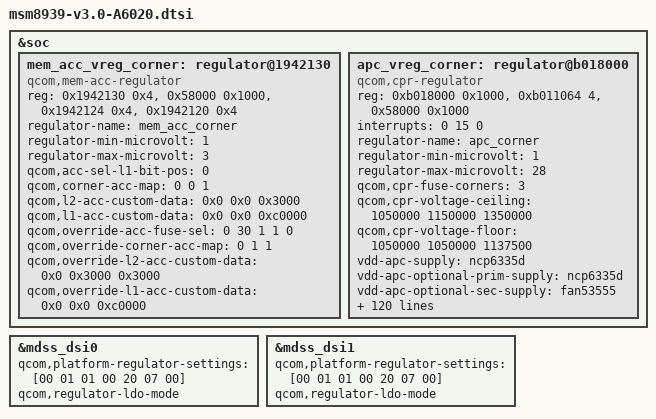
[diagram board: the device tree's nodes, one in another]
/*
 * Copyright (c) 2015, The Linux Foundation. All rights reserved.
 *
 * This program is free software; you can redistribute it and/or modify
 * it under the terms of the GNU General Public License version 2 and
 * only version 2 as published by the Free Software Foundation.
 *
 * This program is distributed in the hope that it will be useful,
 * but WITHOUT ANY WARRANTY; without even the implied warranty of
 * MERCHANTABILITY or FITNESS FOR A PARTICULAR PURPOSE.  See the
 * GNU General Public License for more details.
 */

&soc {
	/delete-node/ regulator@1942130;
        /delete-node/ regulator@b018000;

	mem_acc_vreg_corner: regulator@1942130 {
		compatible = "qcom,mem-acc-regulator";
		reg = <0x1942130 0x4>, <0x58000 0x1000>, <0x1942124 0x4>,  <0x1942120 0x4>;
		reg-names = "acc-sel-l1", "efuse_addr", "acc-l2-custom", "acc-l1-custom";
		regulator-name = "mem_acc_corner";
		regulator-min-microvolt = <1>;
		regulator-max-microvolt = <3>;

		qcom,acc-sel-l1-bit-pos = <0>;
		qcom,corner-acc-map = <0 0 1>;
		qcom,l2-acc-custom-data = <0x0 0x0 0x3000>;
                qcom,l1-acc-custom-data = <0x0 0x0 0xc0000>;

		qcom,override-acc-fuse-sel = <0 30 1 1 0>;
		qcom,override-corner-acc-map = <0 1 1>;
		qcom,override-l2-acc-custom-data = <0x0 0x3000 0x3000>;
                qcom,override-l1-acc-custom-data = <0x0 0x0 0xc0000>;
       };

	apc_vreg_corner: regulator@b018000 {
		compatible = "qcom,cpr-regulator";
		reg = <0xb018000 0x1000>, <0xb011064 4>, <0x58000 0x1000>;
		reg-names = "rbcpr", "rbcpr_clk", "efuse_addr";
		interrupts = <0 15 0>;
		regulator-name = "apc_corner";
		regulator-min-microvolt = <1>;
		regulator-max-microvolt = <28>;

		qcom,cpr-fuse-corners = <3>;
		qcom,cpr-voltage-ceiling = <1050000 1150000 1350000>;
		qcom,cpr-voltage-floor = <1050000 1050000 1137500>;
		vdd-apc-supply = <&ncp6335d>;
		vdd-apc-optional-prim-supply = <&ncp6335d>;
		vdd-apc-optional-sec-supply = <&fan53555>;

		qcom,vdd-mx-corner-map = <4 5 7>;
		qcom,vdd-mx-vmin-method = <4>;
		vdd-mx-supply = <&pm8916_l3_corner_ao>;
		qcom,vdd-mx-vmax = <7>;

		mem-acc-supply = <&mem_acc_vreg_corner>;

		qcom,cpr-ref-clk = <19200>;
		qcom,cpr-timer-delay = <5000>;
		qcom,cpr-timer-cons-up = <0>;
		qcom,cpr-timer-cons-down = <2>;
		qcom,cpr-irq-line = <0>;
		qcom,cpr-step-quotient = <13>;
		qcom,cpr-up-threshold = <0>;
		qcom,cpr-down-threshold = <3>;
		qcom,cpr-idle-clocks = <15>;
		qcom,cpr-gcnt-time = <1>;
		qcom,vdd-apc-step-up-limit = <1>;
		qcom,vdd-apc-step-down-limit = <1>;
		qcom,cpr-apc-volt-step = <6250>;

		qcom,cpr-fuse-row = <27 0>;
		qcom,cpr-fuse-target-quot = <42 24 6>;
		qcom,cpr-fuse-ro-sel = <54 54 54>;
		qcom,cpr-quot-min-diff = <0>;
		qcom,cpr-init-voltage-ref = <1050000 1150000 1350000>;
		qcom,cpr-fuse-init-voltage =
					<27 36 6 0>,
					<27 18 6 0>,
					<27 0 6 0>;
		qcom,cpr-init-voltage-step = <10000>;
		qcom,cpr-scaled-init-voltage-as-ceiling;
		qcom,cpr-corner-map = <1 1 1 2 2 2 2 2 2 2 2 2 2 2 3 3 3 3 3 3
					3 3 3 3 3 3 3 3>;
		qcom,cpr-corner-frequency-map =
					<1 200000000>,
					<2 345600000>,
					<3 400000000>,
					<4 422400000>,
					<5 499200000>,
					<6 533330000>,
					<7 652800000>,
					<8 729600000>,
					<9 800000000>,
					<10 806400000>,
					<11 883200000>,
					<12 960000000>,
					<13 1036800000>,
					<14 1113600000>,
					<15 1190400000>,
					<16 1267200000>,
					<17 1344000000>,
					<18 1363200000>,
					<19 1420800000>,
					<20 1459200000>,
					<21 1497600000>,
					<22 1536000000>,
					<23 1574400000>,
					<24 1612800000>,
					<25 1632000000>,
					<26 1651200000>,
					<27 1689600000>,
					<28 1708800000>;
		qcom,speed-bin-fuse-sel = <1 34 3 0>;
		qcom,cpr-speed-bin-max-corners =
					<0 0 3 14 21>,
					<2 0 3 14 21>,
					<2 2 3 14 20>,
					<4 0 3 14 28>,
					<5 0 3 14 26>,
					<5 6 3 14 26>;
		qcom,cpr-quot-adjust-scaling-factor-max = <900>;
		qcom,fuse-remap-base-row = <1000>;
		qcom,fuse-remap-source =
					<0 29 1 0>, /* speed bit[0]	*/
					<0 50 2 0>, /* speed bit[2:1]	*/
					<0 45 1 0>, /* CPR Rev[0]	*/
					<0 56 1 0>; /* CPR Rev[1]	*/
		qcom,pvs-version-fuse-sel = <1000 0 3 0>;
		qcom,cpr-fuse-revision = <1000 3 2 0>;
		qcom,cpr-fuse-version-map =
		/* <Speed_bits PVS_version CPR_Rev - - -> */
			<0          0          0 0xffffffff 0xffffffff 0xffffffff>,
			<0          0          1 0xffffffff 0xffffffff 0xffffffff>,
			<0          0          2 0xffffffff 0xffffffff 0xffffffff>,
			<0          0          3 0xffffffff 0xffffffff 0xffffffff>,
			<2          0          0 0xffffffff 0xffffffff 0xffffffff>,
			<2          0          1 0xffffffff 0xffffffff 0xffffffff>,
			<2          0          2 0xffffffff 0xffffffff 0xffffffff>,
			<2          0          3 0xffffffff 0xffffffff 0xffffffff>,
			<2          2          0 0xffffffff 0xffffffff 0xffffffff>,
			<2          2          1 0xffffffff 0xffffffff 0xffffffff>,
			<2          2          2 0xffffffff 0xffffffff 0xffffffff>,
			<2          2          3 0xffffffff 0xffffffff 0xffffffff>,
			<0xffffffff 0xffffffff 0 0xffffffff 0xffffffff 0xffffffff>,
			<0xffffffff 0xffffffff 1 0xffffffff 0xffffffff 0xffffffff>,
			<0xffffffff 0xffffffff 2 0xffffffff 0xffffffff 0xffffffff>,
			<0xffffffff 0xffffffff 3 0xffffffff 0xffffffff 0xffffffff>;
		qcom,cpr-init-voltage-adjustment =
					<0   50000  0>,
					<0   20000  0>,
					<0   50000  0>,
					<0   20000  0>,
					<0   20000  0>,
					<0 (-10000) 0>,
					<0   50000  0>,
					<0   20000  0>,
					<0   50000  0>,
					<0   20000  0>,
					<0   50000  0>,
					<0   20000  0>,
					<0   50000  0>,
					<0   20000  0>,
					<0   50000  0>,
					<0   20000  0>;
		qcom,cpr-quotient-adjustment =
					<0  104   (-41)>, /* NOM + 50mv, TURBO - 20mv	*/
					<0   41   (-41)>, /* NOM + 20mv, TURBO - 20mv	*/
					<0  104   (-41)>, /* NOM + 50mv, TURBO - 20mv	*/
					<0   41   (-41)>, /* NOM + 20mv, TURBO - 20mv	*/
					<0  104   (-41)>, /* NOM + 50mv, TURBO - 20mv	*/
					<0   41   (-41)>, /* NOM + 20mv, TURBO - 20mv	*/
					<0  104   (-41)>, /* NOM + 50mv, TURBO - 20mv	*/
					<0   41   (-41)>, /* NOM + 20mv, TURBO - 20mv	*/
					<0   41  (-124)>, /* NOM + 20mv, TURBO - 60mv	*/
					<0 (-20) (-124)>, /* NOM - 10mv, TURBO - 60mv	*/
					<0  104  (-124)>, /* NOM + 50mv, TURBO - 60mv	*/
					<0   41  (-124)>, /* NOM + 20mv, TURBO - 60mv	*/
					<0  104   (-41)>, /* NOM + 50mv, TURBO - 20mv	*/
					<0   41   (-41)>, /* NOM + 20mv, TURBO - 20mv	*/
					<0  104   (-41)>, /* NOM + 50mv, TURBO - 20mv	*/
					<0   41   (-41)>; /* NOM + 20mv, TURBO - 20mv	*/
		qcom,cpr-fuse-min-quot-diff = <0 0 40>;
		qcom,cpr-min-quot-diff-adjustment =
					<0 0 40>,
					<0 0 40>,
					<0 0 40>,
					<0 0 40>,
					<0 0 40>,
					<0 0 40>,
					<0 0 40>,
					<0 0 40>,
					<0 0 62>,
					<0 0 62>,
					<0 0 62>,
					<0 0 62>,
					<0 0 40>,
					<0 0 40>,
					<0 0 40>,
					<0 0 40>;
		qcom,cpr-virtual-corner-quotient-adjustment =
			<0 0 0 (-104) (-104) (-104) (-104) (-104) (-104) (-104)
			 (-104) (-104) (-41) 0 0 0 0 0 0 0 0 0 0 113 0 0 0 0>,
			<0 0 0 (-104) (-104) (-104) (-104) (-104) (-104) (-104)
			 (-104) (-41) (-41) 0 0 0 0 0 0 0 0 0 0 113 0 0 0 0>,
			<0 0 0 (-104) (-104) (-104) (-104) (-104) (-104) (-104)
			 (-104) (-104) (-41) 0 0 0 0 0 0 0 0 0 0 113 0 0 0 0>,
			<0 0 0 (-104) (-104) (-104) (-104) (-104) (-104) (-104)
			 (-104) (-41) (-41) 0 0 0 0 0 0 0 0 0 0 113 0 0 0 0>,
			<0 0 0 (-104) (-104) (-104) (-104) (-104) (-104) (-104)
			 (-104) (-104) (-41) 0 0 0 0 0 0 0 0 0 0 113 0 0 0 0>,
			<0 0 0 (-104) (-104) (-104) (-104) (-104) (-104) (-104)
			 (-104) (-41) (-41) 0 0 0 0 0 0 0 0 0 0 113 0 0 0 0>,
			<0 0 0 (-104) (-104) (-104) (-104) (-104) (-104) (-104)
			 (-104) (-104) (-41) 0 0 0 0 0 0 0 0 0 0 113 0 0 0 0>,
			<0 0 0 (-104) (-104) (-104) (-104) (-104) (-104) (-104)
			 (-104) (-41) (-41) 0 0 0 0 0 0 0 0 0 0 113 0 0 0 0>,
			<0 0 0 (-104) (-104) (-104) (-104) (-104) (-104) (-104)
			 (-104) (-104) (-41) 0 0 0 0 0 0 0 0 0 0 196 0 0 0 0>,
			<0 0 0 (-104) (-104) (-104) (-104) (-104) (-104) (-104)
			 (-104) (-41) (-41) 0 0 0 0 0 0 0 0 0 0 196 0 0 0 0>,
			<0 0 0 (-104) (-104) (-104) (-104) (-104) (-104) (-104)
			 (-104) (-104) (-41) 0 0 0 0 0 0 0 0 0 0 196 0 0 0 0>,
			<0 0 0 (-104) (-104) (-104) (-104) (-104) (-104) (-104)
			 (-104) (-41) (-41) 0 0 0 0 0 0 0 0 0 0 196 0 0 0 0>,
			<0 0 0 (-104) (-104) (-104) (-104) (-104) (-104) (-104)
			 (-104) (-104) (-41) 0 0 0 0 0 0 0 0 0 0 0 0 0 0 0>,
			<0 0 0 (-104) (-104) (-104) (-104) (-104) (-104) (-104)
			 (-104) (-41) (-41) 0 0 0 0 0 0 0 0 0 0 0 0 0 0 0>,
			<0 0 0 (-104) (-104) (-104) (-104) (-104) (-104) (-104)
			 (-104) (-104) (-41) 0 0 0 0 0 0 0 0 0 0 0 0 0 0 0>,
			<0 0 0 (-104) (-104) (-104) (-104) (-104) (-104) (-104)
			 (-104) (-41) (-41) 0 0 0 0 0 0 0 0 0 0 0 0 0 0 0>;
		qcom,cpr-virtual-corner-init-voltage-adjustment =
			<0 0 0 0 0 0 0 0 0 0 0 0 0 0 0 0 0 0 0 0 0 0 0 35000 0 0 0 0>,
			<0 0 0 0 0 0 0 0 0 0 0 0 0 0 0 0 0 0 0 0 0 0 0 35000 0 0 0 0>,
			<0 0 0 0 0 0 0 0 0 0 0 0 0 0 0 0 0 0 0 0 0 0 0 35000 0 0 0 0>,
			<0 0 0 0 0 0 0 0 0 0 0 0 0 0 0 0 0 0 0 0 0 0 0 35000 0 0 0 0>,
			<0 0 0 0 0 0 0 0 0 0 0 0 0 0 0 0 0 0 0 0 0 0 0 35000 0 0 0 0>,
			<0 0 0 0 0 0 0 0 0 0 0 0 0 0 0 0 0 0 0 0 0 0 0 35000 0 0 0 0>,
			<0 0 0 0 0 0 0 0 0 0 0 0 0 0 0 0 0 0 0 0 0 0 0 35000 0 0 0 0>,
			<0 0 0 0 0 0 0 0 0 0 0 0 0 0 0 0 0 0 0 0 0 0 0 35000 0 0 0 0>,
			<0 0 0 0 0 0 0 0 0 0 0 0 0 0 0 0 0 0 0 0 0 0 0 35000 0 0 0 0>,
			<0 0 0 0 0 0 0 0 0 0 0 0 0 0 0 0 0 0 0 0 0 0 0 35000 0 0 0 0>,
			<0 0 0 0 0 0 0 0 0 0 0 0 0 0 0 0 0 0 0 0 0 0 0 35000 0 0 0 0>,
			<0 0 0 0 0 0 0 0 0 0 0 0 0 0 0 0 0 0 0 0 0 0 0 35000 0 0 0 0>,
			<0 0 0 0 0 0 0 0 0 0 0 0 0 0 0 0 0 0 0 0 0 0 0     0 0 0 0 0>,
			<0 0 0 0 0 0 0 0 0 0 0 0 0 0 0 0 0 0 0 0 0 0 0     0 0 0 0 0>,
			<0 0 0 0 0 0 0 0 0 0 0 0 0 0 0 0 0 0 0 0 0 0 0     0 0 0 0 0>,
			<0 0 0 0 0 0 0 0 0 0 0 0 0 0 0 0 0 0 0 0 0 0 0     0 0 0 0 0>;
		qcom,cpr-voltage-floor-override =
			<0xffffffff 0xffffffff 1050000 1050000 1050000 1050000
			1050000 1050000 1050000 1050000 1050000 1050000 1050000
			1050000 1050000 1100000 1137500 1137500 1137500 1137500
			1137500 1137500 1137500 1137500 1137500 1137500 1137500
			1137500 1137500 1137500>;
		qcom,cpr-enable;
	};
};

&mdss_dsi0 {
        qcom,platform-regulator-settings = [00 01 01 00 20 07 00];
        qcom,regulator-ldo-mode;
};

&mdss_dsi1 {
        qcom,platform-regulator-settings = [00 01 01 00 20 07 00];
        qcom,regulator-ldo-mode;
};

